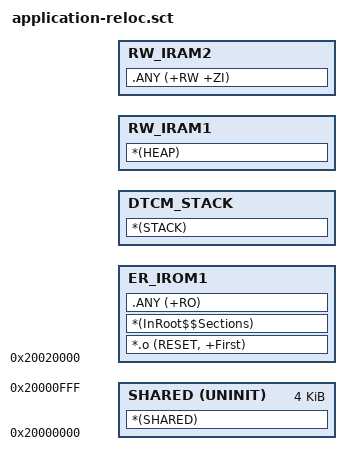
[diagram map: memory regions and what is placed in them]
LR_IROM1 0x20020000 RELOC {    ; load region size_region
  ER_IROM1 +0 {  ; load address = execution address
   *.o (RESET, +First)
   *(InRoot$$Sections)
   .ANY (+RO)
  }
  DTCM_STACK +0  {  ; DTCM    
   *(STACK)
  }
  RW_IRAM1 +0  {  ; SDRAM
    *(HEAP)
  }
  RW_IRAM2 +0 {  ; SDRAM
    .ANY (+RW +ZI)
  }
  SHARED 0x20000000 UNINIT 0x00001000  {  ; DTCM
    *(SHARED)
  }
}

;STM32F769 MEMORY MAP:
;
;SRAM2  (16 KB)     0x2007 C000 - 0x2007 FFFF
;SRAM1  (368 KB)    0x2002 0000 - 0x2007 BFFF
;DTCM   (128 KB)    0x2000 0000 - 0x2001 FFFF
;ITCM RAM (16kb)    0x0000 0000 - 0x0000 3FFF
